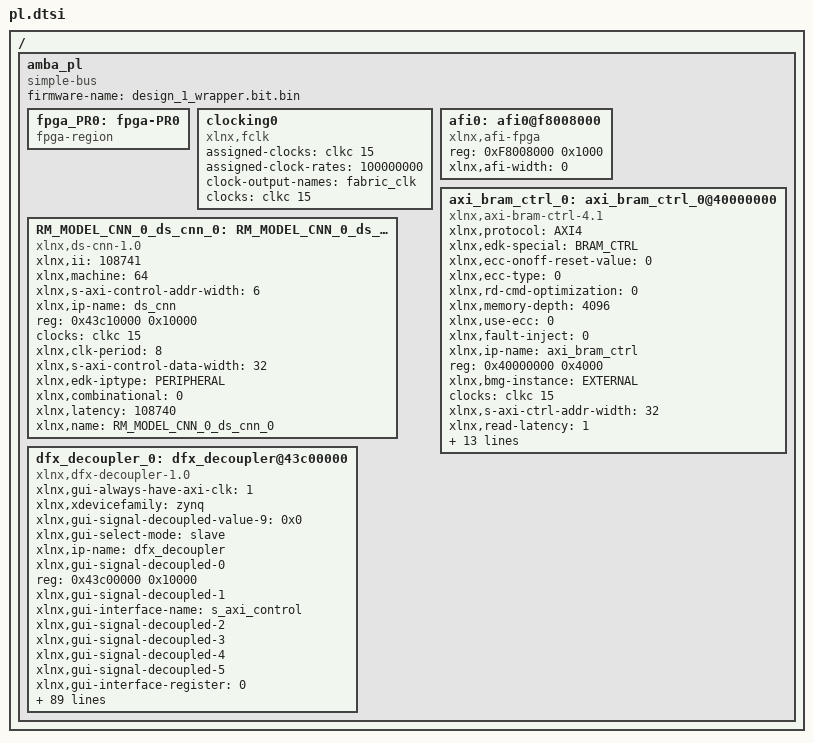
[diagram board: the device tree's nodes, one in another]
/ {
	amba_pl: amba_pl {
		ranges;
		compatible = "simple-bus";
		#address-cells = <1>;
		#size-cells = <1>;
		firmware-name = "design_1_wrapper.bit.bin";
		fpga_PR0: fpga-PR0 {
			ranges;
			compatible = "fpga-region";
			#address-cells = <2>;
			#size-cells = <2>;
		};
		clocking0: clocking0 {
			compatible = "xlnx,fclk";
			assigned-clocks = <&clkc 15>;
			assigned-clock-rates = <100000000>;
			#clock-cells = <0>;
			clock-output-names = "fabric_clk";
			clocks = <&clkc 15>;
		};
		afi0: afi0@f8008000 {
			status = "okay";
			compatible = "xlnx,afi-fpga";
			#address-cells = <1>;
			reg = <0xF8008000 0x1000>;
			#size-cells = <0>;
			xlnx,afi-width = <0>;
		};
		axi_bram_ctrl_0: axi_bram_ctrl_0@40000000 {
			xlnx,protocol = "AXI4";
			xlnx,edk-special = "BRAM_CTRL";
			compatible = "xlnx,axi-bram-ctrl-4.1" , "xlnx,axi-bram-ctrl";
			xlnx,ecc-onoff-reset-value = <0>;
			xlnx,ecc-type = <0>;
			xlnx,rd-cmd-optimization = <0>;
			xlnx,memory-depth = <4096>;
			xlnx,use-ecc = <0>;
			xlnx,fault-inject = <0>;
			xlnx,ip-name = "axi_bram_ctrl";
			reg = <0x40000000 0x4000>;
			xlnx,bmg-instance = "EXTERNAL";
			clocks = <&clkc 15>;
			xlnx,s-axi-ctrl-addr-width = <32>;
			xlnx,read-latency = <1>;
			xlnx,id-width = <0>;
			xlnx,s-axi-supports-narrow-burst = <0>;
			xlnx,supports-narrow-burst = <0>;
			xlnx,single-port-bram = <1>;
			xlnx,ecc = <0>;
			xlnx,edk-iptype = "PERIPHERAL";
			status = "okay";
			clock-names = "s_axi_aclk";
			xlnx,data-width = <32>;
			xlnx,bram-addr-width = <12>;
			xlnx,bram-inst-mode = "EXTERNAL";
			xlnx,s-axi-ctrl-data-width = <32>;
			xlnx,mem-depth = <4096>;
			xlnx,s-axi-id-width = <1>;
			xlnx,name = "axi_bram_ctrl_0";
		};
		RM_MODEL_CNN_0_ds_cnn_0: RM_MODEL_CNN_0_ds_cnn_0@43c10000 {
			compatible = "xlnx,ds-cnn-1.0";
			xlnx,ii = <108741>;
			xlnx,machine = <64>;
			xlnx,s-axi-control-addr-width = <6>;
			xlnx,ip-name = "ds_cnn";
			reg = <0x43c10000 0x10000>;
			clocks = <&clkc 15>;
			xlnx,clk-period = <8>;
			xlnx,s-axi-control-data-width = <32>;
			xlnx,edk-iptype = "PERIPHERAL";
			status = "okay";
			clock-names = "ap_clk";
			xlnx,combinational = <0>;
			xlnx,latency = <108740>;
			xlnx,name = "RM_MODEL_CNN_0_ds_cnn_0";
		};
		dfx_decoupler_0: dfx_decoupler@43c00000 {
			xlnx,gui-always-have-axi-clk = <1>;
			xlnx,xdevicefamily = "zynq";
			xlnx,gui-signal-decoupled-value-9 = <0x0>;
			xlnx,gui-select-mode = "slave";
			xlnx,ip-name = "dfx_decoupler";
			xlnx,gui-signal-decoupled-0;
			reg = <0x43c00000 0x10000>;
			xlnx,gui-signal-decoupled-1;
			xlnx,gui-interface-name = "s_axi_control";
			xlnx,gui-signal-decoupled-2;
			xlnx,gui-signal-decoupled-3;
			xlnx,gui-signal-decoupled-4;
			xlnx,gui-signal-decoupled-5;
			xlnx,gui-interface-register = <0>;
			xlnx,gui-signal-decoupled-6;
			xlnx,gui-signal-decoupled-7;
			xlnx,gui-signal-decoupled-8;
			xlnx,gui-signal-decoupled-9;
			xlnx,gui-signal-width-0 = <1>;
			xlnx,gui-signal-select-0 = "ARVALID";
			compatible = "xlnx,dfx-decoupler-1.0" , "xlnx,pr-decoupler";
			xlnx,gui-has-signal-status = <1>;
			xlnx,gui-signal-width-1 = <1>;
			xlnx,gui-signal-select-1 = "ARREADY";
			xlnx,gui-signal-present-0;
			xlnx,gui-signal-width-2 = <1>;
			xlnx,gui-signal-select-2 = "AWVALID";
			xlnx,gui-signal-present-1;
			xlnx,gui-signal-width-3 = <1>;
			xlnx,gui-signal-select-3 = "AWREADY";
			xlnx,gui-signal-present-2;
			xlnx,gui-signal-width-4 = <1>;
			xlnx,gui-signal-select-4 = "BVALID";
			xlnx,gui-signal-present-3;
			xlnx,gui-has-axis-control = <0>;
			xlnx,gui-signal-width-5 = <1>;
			xlnx,gui-signal-select-5 = "BREADY";
			xlnx,gui-signal-present-4;
			xlnx,gui-signal-management-0 = "auto";
			xlnx,gui-signal-width-6 = <1>;
			xlnx,gui-signal-select-6 = "RVALID";
			xlnx,gui-signal-present-5;
			xlnx,gui-signal-management-1 = "auto";
			xlnx,gui-signal-width-7 = <1>;
			xlnx,gui-signal-select-7 = "RREADY";
			xlnx,gui-signal-present-6;
			xlnx,gui-signal-management-2 = "auto";
			xlnx,gui-signal-width-8 = <1>;
			xlnx,gui-signal-select-8 = "WVALID";
			xlnx,gui-signal-present-7;
			xlnx,gui-signal-management-3 = "auto";
			xlnx,gui-interface-protocol = "axi4lite";
			xlnx,gui-signal-width-9 = <1>;
			xlnx,gui-signal-select-9 = "WREADY";
			xlnx,gui-signal-present-8;
			xlnx,gui-signal-management-4 = "auto";
			xlnx,gui-signal-present-9;
			xlnx,gui-signal-management-5 = "auto";
			xlnx,gui-signal-management-6 = "auto";
			xlnx,gui-select-vlnv = "xilinx.com:interface:aximm_rtl:1.0";
			xlnx,gui-signal-management-7 = "auto";
			status = "okay";
			xlnx,gui-signal-management-8 = "auto";
			xlnx,gui-signal-management-9 = "auto";
			xlnx,gui-select-interface = <0>;
			xlnx,ipi-all-params = "ALWAYS_HAVE_AXI_CLK , 1 , INTF , s_axi_control {ID 0 VLNV xilinx.com:interface:aximm_rtl:1.0 PROTOCOL AXI4LITE SIGNALS {ARVALID {PRESENT 1 WIDTH 1} ARREADY {PRESENT 1 WIDTH 1} AWVALID {PRESENT 1 WIDTH 1} AWREADY {PRESENT 1 WIDTH 1} BVALID {PRESENT 1 WIDTH 1} BREADY {PRESENT 1 WIDTH 1} RVALID {PRESENT 1 WIDTH 1} RREADY {PRESENT 1 WIDTH 1} WVALID {PRESENT 1 WIDTH 1} WREADY {PRESENT 1 WIDTH 1} AWADDR {PRESENT 1 WIDTH 32} AWLEN {PRESENT 0 WIDTH 8} AWSIZE {PRESENT 0 WIDTH 3} AWBURST {PRESENT 0 WIDTH 2} AWLOCK {PRESENT 0 WIDTH 1} AWCACHE {PRESENT 0 WIDTH 4} AWPROT {PRESENT 1 WIDTH 3} WDATA {PRESENT 1 WIDTH 32} WSTRB {PRESENT 1 WIDTH 4} WLAST {PRESENT 0 WIDTH 1} BRESP {PRESENT 1 WIDTH 2} ARADDR {PRESENT 1 WIDTH 32} ARLEN {PRESENT 0 WIDTH 8} ARSIZE {PRESENT 0 WIDTH 3} ARBURST {PRESENT 0 WIDTH 2} ARLOCK {PRESENT 0 WIDTH 1} ARCACHE {PRESENT 0 WIDTH 4} ARPROT {PRESENT 1 WIDTH 3} RDATA {PRESENT 1 WIDTH 32} RRESP {PRESENT 1 WIDTH 2} RLAST {PRESENT 0 WIDTH 1} AWID {WIDTH 0 PRESENT 0} AWREGION {WIDTH 4 PRESENT 0} AWQOS {WIDTH 4 PRESENT 0} AWUSER {WIDTH 0 PRESENT 0} WID {WIDTH 0 PRESENT 0} WUSER {WIDTH 0 PRESENT 0} BID {WIDTH 0 PRESENT 0} BUSER {WIDTH 0 PRESENT 0} ARID {WIDTH 0 PRESENT 0} ARREGION {WIDTH 4 PRESENT 0} ARQOS {WIDTH 4 PRESENT 0} ARUSER {WIDTH 0 PRESENT 0} RID {WIDTH 0 PRESENT 0} RUSER {WIDTH 0 PRESENT 0}} MODE slave} m_axi_gmem {ID 1 VLNV xilinx.com:interface:aximm_rtl:1.0 PROTOCOL AXI4 SIGNALS {ARVALID {WIDTH 1 PRESENT 1} ARREADY {WIDTH 1 PRESENT 1} AWVALID {WIDTH 0 PRESENT 0} AWREADY {WIDTH 0 PRESENT 0} BVALID {WIDTH 0 PRESENT 0} BREADY {WIDTH 0 PRESENT 0} RVALID {WIDTH 1 PRESENT 1} RREADY {WIDTH 1 PRESENT 1} WVALID {WIDTH 0 PRESENT 0} WREADY {WIDTH 0 PRESENT 0} AWID {WIDTH 0 PRESENT 0} AWADDR {WIDTH 0 PRESENT 0} AWLEN {WIDTH 0 PRESENT 0} AWSIZE {WIDTH 0 PRESENT 0} AWBURST {WIDTH 0 PRESENT 0} AWLOCK {WIDTH 0 PRESENT 0} AWCACHE {WIDTH 0 PRESENT 0} AWPROT {WIDTH 0 PRESENT 0} AWREGION {WIDTH 0 PRESENT 0} AWQOS {WIDTH 0 PRESENT 0} AWUSER {WIDTH 0 PRESENT 0} WID {WIDTH 0 PRESENT 0} WDATA {WIDTH 0 PRESENT 0} WSTRB {WIDTH 0 PRESENT 0} WLAST {WIDTH 0 PRESENT 0} WUSER {WIDTH 0 PRESENT 0} BID {WIDTH 0 PRESENT 0} BRESP {WIDTH 0 PRESENT 0} BUSER {WIDTH 0 PRESENT 0} ARID {WIDTH 1 PRESENT 1} ARADDR {WIDTH 64 PRESENT 1} ARLEN {WIDTH 8 PRESENT 1} ARSIZE {WIDTH 3 PRESENT 1} ARBURST {WIDTH 2 PRESENT 0} ARLOCK {WIDTH 1 PRESENT 1} ARCACHE {WIDTH 4 PRESENT 1} ARPROT {WIDTH 3 PRESENT 1} ARREGION {WIDTH 4 PRESENT 1} ARQOS {WIDTH 4 PRESENT 1} ARUSER {WIDTH 0 PRESENT 0} RID {WIDTH 1 PRESENT 1} RDATA {WIDTH 32 PRESENT 1} RRESP {WIDTH 2 PRESENT 1} RLAST {WIDTH 1 PRESENT 1} RUSER {WIDTH 0 PRESENT 0}}} , HAS_SIGNAL_STATUS , 1 , HAS_SIGNAL_CONTROL , 0 , HAS_AXI_LITE , 1";
			xlnx,name = "dfx_decoupler_0";
			xlnx,all-params = "ALWAYS_HAVE_AXI_CLK , 1 , INTF , s_axi_control {ID 0 VLNV xilinx.com:interface:aximm_rtl:1.0 PROTOCOL AXI4LITE SIGNALS {ARVALID {PRESENT 1 WIDTH 1} ARREADY {PRESENT 1 WIDTH 1} AWVALID {PRESENT 1 WIDTH 1} AWREADY {PRESENT 1 WIDTH 1} BVALID {PRESENT 1 WIDTH 1} BREADY {PRESENT 1 WIDTH 1} RVALID {PRESENT 1 WIDTH 1} RREADY {PRESENT 1 WIDTH 1} WVALID {PRESENT 1 WIDTH 1} WREADY {PRESENT 1 WIDTH 1} AWADDR {PRESENT 1 WIDTH 32} AWLEN {PRESENT 0 WIDTH 8} AWSIZE {PRESENT 0 WIDTH 3} AWBURST {PRESENT 0 WIDTH 2} AWLOCK {PRESENT 0 WIDTH 1} AWCACHE {PRESENT 0 WIDTH 4} AWPROT {PRESENT 1 WIDTH 3} WDATA {PRESENT 1 WIDTH 32} WSTRB {PRESENT 1 WIDTH 4} WLAST {PRESENT 0 WIDTH 1} BRESP {PRESENT 1 WIDTH 2} ARADDR {PRESENT 1 WIDTH 32} ARLEN {PRESENT 0 WIDTH 8} ARSIZE {PRESENT 0 WIDTH 3} ARBURST {PRESENT 0 WIDTH 2} ARLOCK {PRESENT 0 WIDTH 1} ARCACHE {PRESENT 0 WIDTH 4} ARPROT {PRESENT 1 WIDTH 3} RDATA {PRESENT 1 WIDTH 32} RRESP {PRESENT 1 WIDTH 2} RLAST {PRESENT 0 WIDTH 1} AWID {WIDTH 0 PRESENT 0} AWREGION {WIDTH 4 PRESENT 0} AWQOS {WIDTH 4 PRESENT 0} AWUSER {WIDTH 0 PRESENT 0} WID {WIDTH 0 PRESENT 0} WUSER {WIDTH 0 PRESENT 0} BID {WIDTH 0 PRESENT 0} BUSER {WIDTH 0 PRESENT 0} ARID {WIDTH 0 PRESENT 0} ARREGION {WIDTH 4 PRESENT 0} ARQOS {WIDTH 4 PRESENT 0} ARUSER {WIDTH 0 PRESENT 0} RID {WIDTH 0 PRESENT 0} RUSER {WIDTH 0 PRESENT 0}} MODE slave} m_axi_gmem {ID 1 VLNV xilinx.com:interface:aximm_rtl:1.0 PROTOCOL AXI4 SIGNALS {ARVALID {WIDTH 1 PRESENT 1} ARREADY {WIDTH 1 PRESENT 1} AWVALID {WIDTH 0 PRESENT 0} AWREADY {WIDTH 0 PRESENT 0} BVALID {WIDTH 0 PRESENT 0} BREADY {WIDTH 0 PRESENT 0} RVALID {WIDTH 1 PRESENT 1} RREADY {WIDTH 1 PRESENT 1} WVALID {WIDTH 0 PRESENT 0} WREADY {WIDTH 0 PRESENT 0} AWID {WIDTH 0 PRESENT 0} AWADDR {WIDTH 0 PRESENT 0} AWLEN {WIDTH 0 PRESENT 0} AWSIZE {WIDTH 0 PRESENT 0} AWBURST {WIDTH 0 PRESENT 0} AWLOCK {WIDTH 0 PRESENT 0} AWCACHE {WIDTH 0 PRESENT 0} AWPROT {WIDTH 0 PRESENT 0} AWREGION {WIDTH 0 PRESENT 0} AWQOS {WIDTH 0 PRESENT 0} AWUSER {WIDTH 0 PRESENT 0} WID {WIDTH 0 PRESENT 0} WDATA {WIDTH 0 PRESENT 0} WSTRB {WIDTH 0 PRESENT 0} WLAST {WIDTH 0 PRESENT 0} WUSER {WIDTH 0 PRESENT 0} BID {WIDTH 0 PRESENT 0} BRESP {WIDTH 0 PRESENT 0} BUSER {WIDTH 0 PRESENT 0} ARID {WIDTH 1 PRESENT 1} ARADDR {WIDTH 64 PRESENT 1} ARLEN {WIDTH 8 PRESENT 1} ARSIZE {WIDTH 3 PRESENT 1} ARBURST {WIDTH 2 PRESENT 0} ARLOCK {WIDTH 1 PRESENT 1} ARCACHE {WIDTH 4 PRESENT 1} ARPROT {WIDTH 3 PRESENT 1} ARREGION {WIDTH 4 PRESENT 1} ARQOS {WIDTH 4 PRESENT 1} ARUSER {WIDTH 0 PRESENT 0} RID {WIDTH 1 PRESENT 1} RDATA {WIDTH 32 PRESENT 1} RRESP {WIDTH 2 PRESENT 1} RLAST {WIDTH 1 PRESENT 1} RUSER {WIDTH 0 PRESENT 0}}} , HAS_SIGNAL_STATUS , 1 , HAS_SIGNAL_CONTROL , 0 , HAS_AXI_LITE , 1";
			xlnx,gui-has-axi-lite;
			clocks = <&clkc 15>, <&clkc 15>, <&clkc 15>;
			xlnx,edk-iptype = "PERIPHERAL";
			clock-names = "aclk" , "m_axi_gmem_aclk" , "s_axi_control_aclk";
			xlnx,gui-signal-resource-0 = "infer";
			xlnx,gui-signal-resource-1 = "infer";
			xlnx,gui-signal-direction-0 = "s";
			xlnx,gui-signal-resource-2 = "infer";
			xlnx,gui-signal-direction-1 = "s";
			xlnx,gui-signal-resource-3 = "infer";
			xlnx,gui-signal-direction-2 = "s";
			xlnx,gui-signal-resource-4 = "infer";
			xlnx,gui-signal-direction-3 = "s";
			xlnx,gui-signal-resource-5 = "infer";
			xlnx,gui-signal-direction-4 = "s";
			xlnx,gui-signal-resource-6 = "infer";
			xlnx,gui-signal-direction-5 = "s";
			xlnx,gui-signal-resource-7 = "infer";
			xlnx,gui-has-axis-status = <0>;
			xlnx,gui-signal-decoupled-value-0 = <0x0>;
			xlnx,gui-signal-direction-6 = "s";
			xlnx,gui-signal-resource-8 = "infer";
			xlnx,gui-signal-decoupled-value-1 = <0x0>;
			xlnx,gui-signal-direction-7 = "s";
			xlnx,gui-signal-resource-9 = "infer";
			xlnx,gui-signal-direction-8 = "s";
			xlnx,gui-signal-decoupled-value-2 = <0x0>;
			xlnx,gui-signal-direction-9 = "s";
			xlnx,gui-signal-decoupled-value-3 = <0x0>;
			xlnx,gui-select-cdc-stages = <0>;
			xlnx,gui-signal-decoupled-value-4 = <0x0>;
			xlnx,gui-signal-decoupled-value-5 = <0x0>;
			xlnx,gui-signal-decoupled-value-6 = <0x0>;
			xlnx,gui-signal-decoupled-value-7 = <0x0>;
			xlnx,gui-signal-decoupled-value-8 = <0x0>;
		};
	};
};
